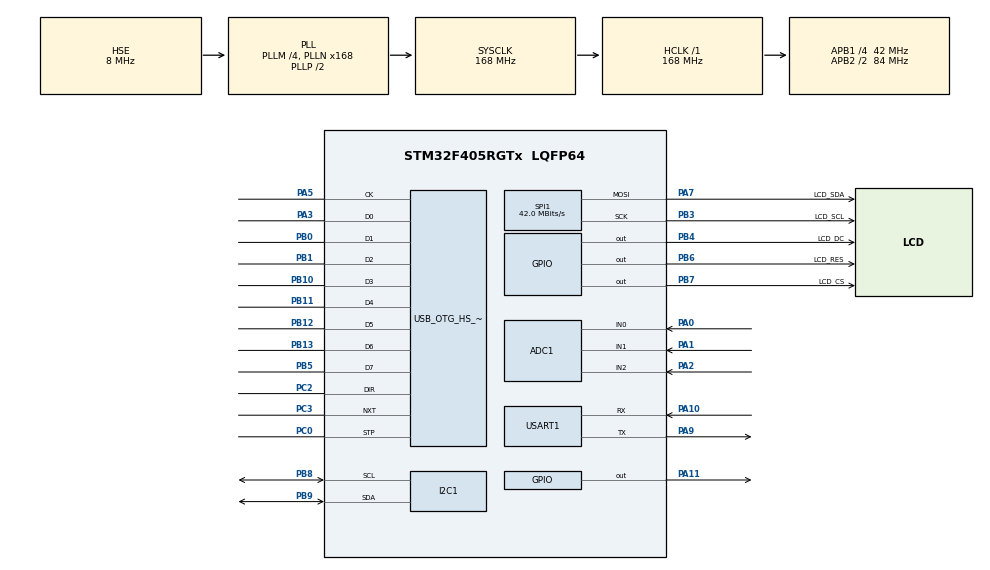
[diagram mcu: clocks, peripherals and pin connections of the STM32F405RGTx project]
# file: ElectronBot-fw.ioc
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ADC1.Channel-0\#ChannelRegularConversion=ADC_CHANNEL_0
ADC1.NbrOfConversionFlag=1
ADC1.Rank-0\#ChannelRegularConversion=1
ADC1.SamplingTime-0\#ChannelRegularConversion=ADC_SAMPLETIME_3CYCLES
ADC1.master=1
Dma.Request0=SPI1_TX
Dma.Request1=USART1_RX
Dma.Request2=USART1_TX
Dma.SPI1_TX.0.Direction=DMA_MEMORY_TO_PERIPH
Dma.SPI1_TX.0.FIFOMode=DMA_FIFOMODE_DISABLE
Dma.SPI1_TX.0.Instance=DMA2_Stream3
Dma.SPI1_TX.0.MemDataAlignment=DMA_MDATAALIGN_BYTE
Dma.SPI1_TX.0.MemInc=DMA_MINC_ENABLE
Dma.SPI1_TX.0.Mode=DMA_NORMAL
Dma.SPI1_TX.0.PeriphDataAlignment=DMA_PDATAALIGN_BYTE
Dma.SPI1_TX.0.PeriphInc=DMA_PINC_DISABLE
Dma.SPI1_TX.0.Priority=DMA_PRIORITY_LOW
Dma.USART1_RX.1.Direction=DMA_PERIPH_TO_MEMORY
Dma.USART1_RX.1.FIFOMode=DMA_FIFOMODE_DISABLE
Dma.USART1_RX.1.Instance=DMA2_Stream2
Dma.USART1_RX.1.MemDataAlignment=DMA_MDATAALIGN_BYTE
Dma.USART1_RX.1.MemInc=DMA_MINC_ENABLE
Dma.USART1_RX.1.Mode=DMA_CIRCULAR
Dma.USART1_RX.1.PeriphDataAlignment=DMA_PDATAALIGN_BYTE
Dma.USART1_RX.1.PeriphInc=DMA_PINC_DISABLE
Dma.USART1_RX.1.Priority=DMA_PRIORITY_LOW
Dma.USART1_TX.2.Direction=DMA_MEMORY_TO_PERIPH
Dma.USART1_TX.2.FIFOMode=DMA_FIFOMODE_DISABLE
Dma.USART1_TX.2.Instance=DMA2_Stream7
Dma.USART1_TX.2.MemDataAlignment=DMA_MDATAALIGN_BYTE
Dma.USART1_TX.2.MemInc=DMA_MINC_ENABLE
Dma.USART1_TX.2.Mode=DMA_NORMAL
Dma.USART1_TX.2.PeriphDataAlignment=DMA_PDATAALIGN_BYTE
Dma.USART1_TX.2.PeriphInc=DMA_PINC_DISABLE
Dma.USART1_TX.2.Priority=DMA_PRIORITY_LOW
FREERTOS.Tasks01=defaultTask,24,128,StartDefaultTask,Default,NULL,Dynamic,NULL,NULL
FREERTOS.configENABLE_FPU=1
FREERTOS.configTOTAL_HEAP_SIZE=10000
I2C1.I2C_Mode=I2C_Standard
Mcu.Family=STM32F4
Mcu.Name=STM32F405RGTx
Mcu.Package=LQFP64
NVIC.DMA2_Stream2_IRQn=true\:5\:0\:false\:false\:true\:true\:false\:true\:true
NVIC.DMA2_Stream3_IRQn=true\:5\:0\:false\:false\:true\:true\:false\:true\:true
NVIC.DMA2_Stream7_IRQn=true\:5\:0\:false\:false\:true\:true\:false\:true\:true
NVIC.OTG_HS_EP1_IN_IRQn=true\:5\:0\:false\:false\:true\:true\:true\:true\:true
NVIC.OTG_HS_EP1_OUT_IRQn=true\:5\:0\:false\:false\:true\:true\:true\:true\:true
NVIC.OTG_HS_IRQn=true\:5\:0\:false\:false\:true\:true\:false\:true\:true
NVIC.PriorityGroup=NVIC_PRIORITYGROUP_4
NVIC.SPI1_IRQn=true\:5\:0\:false\:false\:true\:true\:true\:true\:true
NVIC.TIM8_TRG_COM_TIM14_IRQn=true\:0\:0\:false\:false\:true\:false\:false\:true\:true
NVIC.TimeBase=TIM8_TRG_COM_TIM14_IRQn
NVIC.TimeBaseIP=TIM14
NVIC.USART1_IRQn=true\:5\:0\:false\:false\:true\:true\:true\:true\:true
PA0-WKUP.Signal=ADCx_IN0
PA1.Signal=ADCx_IN1
PA10.Mode=Asynchronous
PA10.Signal=USART1_RX
PA11.Signal=GPIO_Output
PA13.Mode=Serial_Wire
PA13.Signal=SYS_JTMS-SWDIO
PA14.Mode=Serial_Wire
PA14.Signal=SYS_JTCK-SWCLK
PA2.Signal=ADCx_IN2
PA3.Mode=Device_HS
PA3.Signal=USB_OTG_HS_ULPI_D0
PA5.Mode=Device_HS
PA5.Signal=USB_OTG_HS_ULPI_CK
PA7.GPIO_Label=LCD_SDA
PA7.Mode=TX_Only_Simplex_Unidirect_Master
PA7.Signal=SPI1_MOSI
PA9.Mode=Asynchronous
PA9.Signal=USART1_TX
PB0.Mode=Device_HS
PB0.Signal=USB_OTG_HS_ULPI_D1
PB1.Mode=Device_HS
PB1.Signal=USB_OTG_HS_ULPI_D2
PB10.Mode=Device_HS
PB10.Signal=USB_OTG_HS_ULPI_D3
PB11.Mode=Device_HS
PB11.Signal=USB_OTG_HS_ULPI_D4
PB12.Mode=Device_HS
PB12.Signal=USB_OTG_HS_ULPI_D5
PB13.Mode=Device_HS
PB13.Signal=USB_OTG_HS_ULPI_D6
PB3.GPIO_Label=LCD_SCL
PB3.Mode=TX_Only_Simplex_Unidirect_Master
PB3.Signal=SPI1_SCK
PB4.GPIO_Label=LCD_DC
PB4.GPIO_Speed=GPIO_SPEED_FREQ_VERY_HIGH
PB4.Signal=GPIO_Output
PB5.Mode=Device_HS
PB5.Signal=USB_OTG_HS_ULPI_D7
PB6.GPIO_Label=LCD_RES
PB6.GPIO_Speed=GPIO_SPEED_FREQ_VERY_HIGH
PB6.Signal=GPIO_Output
PB7.GPIO_Label=LCD_CS
PB7.GPIO_Speed=GPIO_SPEED_FREQ_VERY_HIGH
PB7.Signal=GPIO_Output
PB8.Mode=I2C
PB8.Signal=I2C1_SCL
PB9.Mode=I2C
PB9.Signal=I2C1_SDA
PC0.Mode=Device_HS
PC0.Signal=USB_OTG_HS_ULPI_STP
PC2.Mode=Device_HS
PC2.Signal=USB_OTG_HS_ULPI_DIR
PC3.Mode=Device_HS
PC3.Signal=USB_OTG_HS_ULPI_NXT
PH0-OSC_IN.Mode=HSE-External-Oscillator
PH0-OSC_IN.Signal=RCC_OSC_IN
PH1-OSC_OUT.Mode=HSE-External-Oscillator
PH1-OSC_OUT.Signal=RCC_OSC_OUT
ProjectManager.HeapSize=0x800
ProjectManager.StackSize=0x800
ProjectManager.TargetToolchain=SW4STM32
RCC.48MHZClocksFreq_Value=48000000
RCC.AHBFreq_Value=168000000
RCC.APB1CLKDivider=RCC_HCLK_DIV4
RCC.APB1Freq_Value=42000000
RCC.APB1TimFreq_Value=84000000
RCC.APB2CLKDivider=RCC_HCLK_DIV2
RCC.APB2Freq_Value=84000000
RCC.APB2TimFreq_Value=168000000
RCC.CortexFreq_Value=168000000
RCC.HCLKFreq_Value=168000000
RCC.HSE_VALUE=8000000
RCC.HSI_VALUE=16000000
RCC.LSE_VALUE=32768
RCC.PLLM=4
RCC.PLLN=168
RCC.PLLQ=7
RCC.PLLSourceVirtual=RCC_PLLSOURCE_HSE
RCC.SYSCLKFreq_VALUE=168000000
RCC.SYSCLKSource=RCC_SYSCLKSOURCE_PLLCLK
RCC.VCOOutputFreq_Value=336000000
SH.ADCx_IN0.0=ADC1_IN0,IN0
SH.ADCx_IN1.0=ADC1_IN1,IN1
SH.ADCx_IN2.0=ADC1_IN2,IN2
SPI1.BaudRatePrescaler=SPI_BAUDRATEPRESCALER_2
SPI1.CalculateBaudRate=42.0 MBits/s
SPI1.Direction=SPI_DIRECTION_2LINES
SPI1.Mode=SPI_MODE_MASTER
SPI1.VirtualType=VM_MASTER
USART1.VirtualMode=VM_ASYNC
USB_DEVICE.APP_RX_DATA_SIZE-CDC_HS=4
USB_DEVICE.APP_TX_DATA_SIZE-CDC_HS=4
USB_DEVICE.CLASS_NAME_HS=CDC
USB_DEVICE.PID_CDC_HS=32803
USB_DEVICE.VID-CDC_HS=4097
USB_DEVICE.VirtualMode-CDC_HS=Cdc
USB_DEVICE.VirtualModeHS=Cdc_HS
USB_OTG_HS.VirtualMode-Device_HS=Device_HS
USB_OTG_HS.dma_enable-Device_HS=ENABLE
VP_FREERTOS_VS_CMSIS_V2.Mode=CMSIS_V2
VP_SYS_VS_tim14.Mode=TIM14
VP_USB_DEVICE_VS_USB_DEVICE_CDC_HS.Mode=CDC_HS
board=custom

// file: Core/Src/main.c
/* USER CODE BEGIN Header */
/**
  ******************************************************************************
  * @file           : main.c
  * @brief          : Main program body
  ******************************************************************************
  * @attention
  *
  * <h2><center>&copy; Copyright (c) 2021 STMicroelectronics.
  * All rights reserved.</center></h2>
  *
  * This software component is licensed by ST under BSD 3-Clause license,
  * the "License"; You may not use this file except in compliance with the
  * License. You may obtain a copy of the License at:
  *                        opensource.org/licenses/BSD-3-Clause
  *
  ******************************************************************************
  */
/* USER CODE END Header */
#include "main.h"
#include "cmsis_os.h"
#include "adc.h"
#include "dma.h"
#include "i2c.h"
#include "spi.h"
#include "usart.h"
#include "usb_device.h"
#include "gpio.h"

/* USER CODE BEGIN PV */

// uint8_t completed = 1;

/* USER CODE END PV */

void SystemClock_Config(void);
void MX_FREERTOS_Init(void);

int main(void)
{

  /* MCU Configuration--------------------------------------------------------*/

  /* Reset of all peripherals, Initializes the Flash interface and the Systick. */
  HAL_Init();

  /* USER CODE BEGIN Init */
    HAL_RCC_DeInit();
  /* USER CODE END Init */

  /* Configure the system clock */
  SystemClock_Config();

  /* Initialize all configured peripherals */
  MX_GPIO_Init();
  MX_DMA_Init();
  MX_ADC1_Init();
  MX_SPI1_Init();
  MX_USART1_UART_Init();
  MX_I2C1_Init();

  /* Init scheduler */

   // MX_DMA_Init();
   // MX_USART1_UART_Init();
   // HAL_UART_Receive_DMA(&huart1,(uint8_t*)ReceiveBuff,BUFFERSIZE);
  //  __HAL_UART_ENABLE_IT(&huart1, UART_IT_IDLE);
  //  while(1){
  //      uart1_data();
  //  }

  osKernelInitialize();  /* Call init function for freertos objects (in freertos.c) */
  MX_FREERTOS_Init();
  /* Start scheduler */
  osKernelStart();

  /* We should never get here as control is now taken by the scheduler */
  /* Infinite loop */
    while (1)
    {

    }
}

void SystemClock_Config(void)
{
  RCC_OscInitTypeDef RCC_OscInitStruct = {0};
  RCC_ClkInitTypeDef RCC_ClkInitStruct = {0};

  /** Configure the main internal regulator output voltage
  */
  __HAL_RCC_PWR_CLK_ENABLE();
  __HAL_PWR_VOLTAGESCALING_CONFIG(PWR_REGULATOR_VOLTAGE_SCALE1);
  /** Initializes the RCC Oscillators according to the specified parameters
  * in the RCC_OscInitTypeDef structure.
  */
  RCC_OscInitStruct.OscillatorType = RCC_OSCILLATORTYPE_HSE;
  RCC_OscInitStruct.HSEState = RCC_HSE_ON;
  RCC_OscInitStruct.PLL.PLLState = RCC_PLL_ON;
  RCC_OscInitStruct.PLL.PLLSource = RCC_PLLSOURCE_HSE;
  RCC_OscInitStruct.PLL.PLLM = 4;
  RCC_OscInitStruct.PLL.PLLN = 168;
  RCC_OscInitStruct.PLL.PLLP = RCC_PLLP_DIV2;
  RCC_OscInitStruct.PLL.PLLQ = 7;
  if (HAL_RCC_OscConfig(&RCC_OscInitStruct) != HAL_OK)
  {
    Error_Handler();
  }
  /** Initializes the CPU, AHB and APB buses clocks
  */
  RCC_ClkInitStruct.ClockType = RCC_CLOCKTYPE_HCLK|RCC_CLOCKTYPE_SYSCLK
                              |RCC_CLOCKTYPE_PCLK1|RCC_CLOCKTYPE_PCLK2;
  RCC_ClkInitStruct.SYSCLKSource = RCC_SYSCLKSOURCE_PLLCLK;
  RCC_ClkInitStruct.AHBCLKDivider = RCC_SYSCLK_DIV1;
  RCC_ClkInitStruct.APB1CLKDivider = RCC_HCLK_DIV4;
  RCC_ClkInitStruct.APB2CLKDivider = RCC_HCLK_DIV2;

  if (HAL_RCC_ClockConfig(&RCC_ClkInitStruct, FLASH_LATENCY_5) != HAL_OK)
  {
    Error_Handler();
  }
}

 /**
  * @brief  Period elapsed callback in non blocking mode
  * @note   This function is called  when TIM14 interrupt took place, inside
  * HAL_TIM_IRQHandler(). It makes a direct call to HAL_IncTick() to increment
  * a global variable "uwTick" used as application time base.
  * @param  htim : TIM handle
  * @retval None
  */
void HAL_TIM_PeriodElapsedCallback(TIM_HandleTypeDef *htim)
{
  if (htim->Instance == TIM14) {
    HAL_IncTick();
  }
}

void Error_Handler(void)
{
    __disable_irq();
    while (1)
    {
    }
}

/************************ (C) COPYRIGHT STMicroelectronics *****END OF FILE****/

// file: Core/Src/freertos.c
/* USER CODE BEGIN Header */
/**
  ******************************************************************************
  * File Name          : freertos.c
  * Description        : Code for freertos applications
  ******************************************************************************
  * @attention
  *
  * <h2><center>&copy; Copyright (c) 2022 STMicroelectronics.
  * All rights reserved.</center></h2>
  *
  * This software component is licensed by ST under Ultimate Liberty license
  * SLA0044, the "License"; You may not use this file except in compliance with
  * the License. You may obtain a copy of the License at:
  *                             www.st.com/SLA0044
  *
  ******************************************************************************
  */
/* USER CODE END Header */

#include "FreeRTOS.h"
#include "task.h"
#include "main.h"
#include "cmsis_os.h"

/* USER CODE BEGIN Includes */
#include "common_inc.h"
/* USER CODE END Includes */

/* USER CODE BEGIN Variables */
//__attribute__((section(".ccmram"))) uint8_t ucHeap[configTOTAL_HEAP_SIZE];

/* USER CODE END Variables */
/* Definitions for defaultTask */
osThreadId_t defaultTaskHandle;
const osThreadAttr_t defaultTask_attributes = {
  .name = "defaultTask",
  //.stack_size = 128 * 4,
  .stack_size = 128 * 8*2,
  .priority = (osPriority_t) osPriorityNormal,
};

void StartDefaultTask(void *argument);

extern void MX_USB_DEVICE_Init(void);
void MX_FREERTOS_Init(void); /* (MISRA C 2004 rule 8.1) */

void MX_FREERTOS_Init(void) {

  /* Create the thread(s) */
  /* creation of defaultTask */
  defaultTaskHandle = osThreadNew(StartDefaultTask, NULL, &defaultTask_attributes);

}

void StartDefaultTask(void *argument)
{
  /* init code for USB_DEVICE */
  MX_USB_DEVICE_Init();
  /* USER CODE BEGIN StartDefaultTask */

    // Invoke cpp-version main().
    Main();
    vTaskDelete(defaultTaskHandle);
  /* USER CODE END StartDefaultTask */
}

/************************ (C) COPYRIGHT STMicroelectronics *****END OF FILE****/
